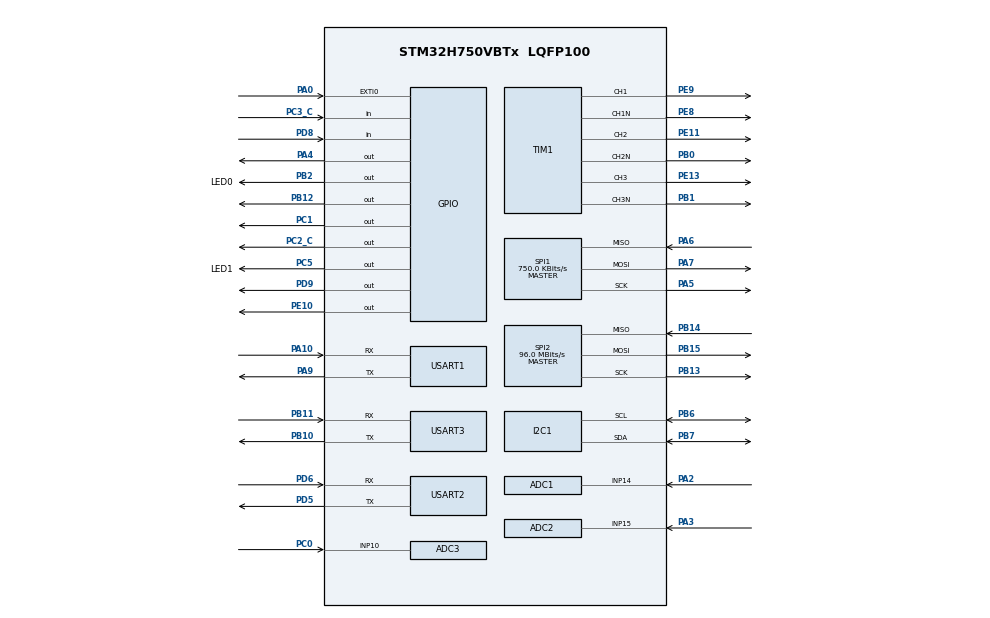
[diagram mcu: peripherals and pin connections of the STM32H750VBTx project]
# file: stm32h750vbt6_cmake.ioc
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ADC1.Channel-5\#ChannelRegularConversion=ADC_CHANNEL_14
ADC1.ClockPrescaler=ADC_CLOCK_ASYNC_DIV1
ADC1.DiscontinuousConvMode=ENABLE
ADC1.NbrOfConversion=1
ADC1.NbrOfConversionFlag=1
ADC1.NbrOfDiscConversion=1
ADC1.OffsetNumber-5\#ChannelRegularConversion=ADC_OFFSET_NONE
ADC1.OffsetSignedSaturation-5\#ChannelRegularConversion=DISABLE
ADC1.OversamplingMode=DISABLE
ADC1.Rank-5\#ChannelRegularConversion=1
ADC1.Ratio=1
ADC1.Resolution=ADC_RESOLUTION_16B
ADC1.SamplingTime-5\#ChannelRegularConversion=ADC_SAMPLETIME_1CYCLE_5
ADC1.master=1
ADC2.Channel-6\#ChannelRegularConversion=ADC_CHANNEL_15
ADC2.NbrOfConversionFlag=1
ADC2.OffsetNumber-6\#ChannelRegularConversion=ADC_OFFSET_NONE
ADC2.OffsetSignedSaturation-6\#ChannelRegularConversion=DISABLE
ADC2.Rank-6\#ChannelRegularConversion=1
ADC2.SamplingTime-6\#ChannelRegularConversion=ADC_SAMPLETIME_1CYCLE_5
ADC3.Channel-1\#ChannelRegularConversion=ADC_CHANNEL_10
ADC3.DiscontinuousConvMode=ENABLE
ADC3.NbrOfConversionFlag=1
ADC3.OffsetNumber-1\#ChannelRegularConversion=ADC_OFFSET_NONE
ADC3.OffsetSignedSaturation-1\#ChannelRegularConversion=DISABLE
ADC3.Rank-1\#ChannelRegularConversion=1
ADC3.SamplingTime-1\#ChannelRegularConversion=ADC_SAMPLETIME_1CYCLE_5
CORTEX_M7.default_mode_Activation=1
I2C1.Timing=0x307075B1
Mcu.Family=STM32H7
Mcu.Name=STM32H750VBTx
Mcu.Package=LQFP100
NVIC.ADC3_IRQn=true\:0\:0\:false\:false\:true\:true\:true\:true
NVIC.ADC_IRQn=true\:0\:0\:false\:false\:true\:true\:true\:true
NVIC.PriorityGroup=NVIC_PRIORITYGROUP_4
NVIC.SPI2_IRQn=true\:0\:0\:false\:false\:true\:true\:true\:true
NVIC.TIM1_BRK_IRQn=true\:0\:0\:false\:false\:true\:true\:true\:true
NVIC.TIM1_CC_IRQn=true\:0\:0\:false\:false\:true\:true\:true\:true
NVIC.TIM1_TRG_COM_IRQn=true\:0\:0\:false\:false\:true\:true\:true\:true
NVIC.TIM1_UP_IRQn=true\:0\:0\:false\:false\:true\:true\:true\:true
NVIC.TIM2_IRQn=true\:0\:0\:false\:false\:true\:true\:true\:true
NVIC.TIM3_IRQn=true\:0\:0\:false\:false\:true\:true\:true\:true
NVIC.TIM4_IRQn=true\:0\:0\:false\:false\:true\:true\:true\:true
NVIC.USART1_IRQn=true\:0\:0\:false\:false\:true\:true\:true\:true
NVIC.USART2_IRQn=true\:0\:0\:false\:false\:true\:true\:true\:true
NVIC.USART3_IRQn=true\:0\:0\:false\:false\:true\:true\:true\:true
PA0.Signal=GPXTI0
PA10.Mode=Asynchronous
PA10.Signal=USART1_RX
PA2.Signal=ADCx_INP14
PA3.Signal=ADCx_INP15
PA4.Signal=GPIO_Output
PA5.Mode=Full_Duplex_Master
PA5.Signal=SPI1_SCK
PA6.Mode=Full_Duplex_Master
PA6.Signal=SPI1_MISO
PA7.Mode=Full_Duplex_Master
PA7.Signal=SPI1_MOSI
PA9.Mode=Asynchronous
PA9.Signal=USART1_TX
PB0.Mode=PWM Generation2 CH2 CH2N
PB0.Signal=TIM1_CH2N
PB1.Mode=PWM Generation3 CH3 CH3N
PB1.Signal=TIM1_CH3N
PB10.Mode=Asynchronous
PB10.Signal=USART3_TX
PB11.Mode=Asynchronous
PB11.Signal=USART3_RX
PB12.Signal=GPIO_Output
PB13.Mode=Full_Duplex_Master
PB13.Signal=SPI2_SCK
PB14.Mode=Full_Duplex_Master
PB14.Signal=SPI2_MISO
PB15.Mode=Full_Duplex_Master
PB15.Signal=SPI2_MOSI
PB2.GPIO_Label=LED0
PB2.Signal=GPIO_Output
PB6.Mode=I2C
PB6.Signal=I2C1_SCL
PB7.Mode=I2C
PB7.Signal=I2C1_SDA
PC0.Signal=ADCx_INP10
PC1.Signal=GPIO_Output
PC2_C.Signal=GPIO_Output
PC3_C.Signal=GPIO_Input
PC5.GPIO_Label=LED1
PC5.Signal=GPIO_Output
PD5.Mode=Asynchronous
PD5.Signal=USART2_TX
PD6.Mode=Asynchronous
PD6.Signal=USART2_RX
PD8.Signal=GPIO_Input
PD9.Signal=GPIO_Output
PE10.Signal=GPIO_Output
PE11.Signal=S_TIM1_CH2
PE13.Signal=S_TIM1_CH3
PE8.Mode=PWM Generation1 CH1 CH1N
PE8.Signal=TIM1_CH1N
PE9.Signal=S_TIM1_CH1
PH0-OSC_IN\ (PH0).Mode=HSE-External-Oscillator
PH0-OSC_IN\ (PH0).Signal=RCC_OSC_IN
PH1-OSC_OUT\ (PH1).Mode=HSE-External-Oscillator
PH1-OSC_OUT\ (PH1).Signal=RCC_OSC_OUT
ProjectManager.HeapSize=0x200
ProjectManager.StackSize=0x400
ProjectManager.TargetToolchain=CMake
RCC.ADCFreq_Value=75000000
RCC.APB1Freq_Value=120000000
RCC.APB2Freq_Value=120000000
RCC.APB3Freq_Value=120000000
RCC.APB4Freq_Value=120000000
RCC.CortexFreq_Value=480000000
RCC.D1PPRE=RCC_APB3_DIV2
RCC.D2PPRE1=RCC_APB1_DIV2
RCC.D2PPRE2=RCC_APB2_DIV2
RCC.D3PPRE=RCC_APB4_DIV2
RCC.DIVM1=5
RCC.DIVM2=2
RCC.DIVN1=192
RCC.DIVN2=12
RCC.DIVQ1=5
RCC.HCLKFreq_Value=240000000
RCC.HPRE=RCC_HCLK_DIV2
RCC.PLL2FRACN=0
RCC.PLLFRACN=0
RCC.PLLSourceVirtual=RCC_PLLSOURCE_HSE
RCC.SYSCLKFreq_VALUE=480000000
RCC.SYSCLKSource=RCC_SYSCLKSOURCE_PLLCLK
RCC.USBFreq_Value=192000000
SH.ADCx_INP10.0=ADC3_INP10,IN10-Single-Ended
SH.ADCx_INP14.0=ADC1_INP14,IN14-Single-Ended
SH.ADCx_INP15.0=ADC2_INP15,IN15-Single-Ended
SH.S_TIM1_CH1.0=TIM1_CH1,PWM Generation1 CH1 CH1N
SH.S_TIM1_CH2.0=TIM1_CH2,PWM Generation2 CH2 CH2N
SH.S_TIM1_CH3.0=TIM1_CH3,PWM Generation3 CH3 CH3N
SPI1.BaudRatePrescaler=SPI_BAUDRATEPRESCALER_256
SPI1.CLKPhase=SPI_PHASE_2EDGE
SPI1.CalculateBaudRate=750.0 KBits/s
SPI1.DataSize=SPI_DATASIZE_8BIT
SPI1.Direction=SPI_DIRECTION_2LINES
SPI1.Mode=SPI_MODE_MASTER
SPI1.VirtualType=VM_MASTER
SPI2.CalculateBaudRate=96.0 MBits/s
SPI2.Direction=SPI_DIRECTION_2LINES
SPI2.Mode=SPI_MODE_MASTER
SPI2.VirtualType=VM_MASTER
TIM1.AutoReloadPreload=TIM_AUTORELOAD_PRELOAD_ENABLE
TIM1.Channel-PWM\ Generation1\ CH1\ CH1N=TIM_CHANNEL_1
TIM1.Channel-PWM\ Generation2\ CH2\ CH2N=TIM_CHANNEL_2
TIM1.Channel-PWM\ Generation3\ CH3\ CH3N=TIM_CHANNEL_3
TIM1.DeadTime=100
TIM3.AutoReloadPreload=TIM_AUTORELOAD_PRELOAD_ENABLE
USART1.VirtualMode-Asynchronous=VM_ASYNC
USART2.VirtualMode-Asynchronous=VM_ASYNC
USART3.VirtualMode-Asynchronous=VM_ASYNC
VP_MEMORYMAP_VS_MEMORYMAP.Mode=CurAppReg
VP_TIM1_VS_ClockSourceINT.Mode=Internal
VP_TIM2_VS_ClockSourceINT.Mode=Internal
VP_TIM3_VS_ClockSourceINT.Mode=Internal
VP_TIM4_VS_ClockSourceINT.Mode=Internal
board=custom

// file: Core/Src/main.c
/* USER CODE BEGIN Header */
/**
  ******************************************************************************
  * @file           : main.c
  * @brief          : Main program body
  ******************************************************************************
  * @attention
  *
  * Copyright (c) 2025 STMicroelectronics.
  * All rights reserved.
  *
  * This software is licensed under terms that can be found in the LICENSE file
  * in the root directory of this software component.
  * If no LICENSE file comes with this software, it is provided AS-IS.
  *
  ******************************************************************************
  */
/* USER CODE END Header */
#include "main.h"
#include "adc.h"
#include "i2c.h"
#include "spi.h"
#include "tim.h"
#include "usart.h"
#include "gpio.h"

/* USER CODE BEGIN Includes */
#include "mymain.h"

/* USER CODE END Includes */

void SystemClock_Config(void);
void PeriphCommonClock_Config(void);
static void MPU_Config(void);

int main(void)
{

  /* MPU Configuration--------------------------------------------------------*/
  MPU_Config();

  /* MCU Configuration--------------------------------------------------------*/

  /* Reset of all peripherals, Initializes the Flash interface and the Systick. */
  HAL_Init();

  /* Configure the system clock */
  SystemClock_Config();

  /* Configure the peripherals common clocks */
  PeriphCommonClock_Config();

  /* Initialize all configured peripherals */
  MX_GPIO_Init();
  MX_USART1_UART_Init();
  MX_I2C1_Init();
  MX_SPI1_Init();
  MX_TIM1_Init();
  MX_TIM2_Init();
  MX_TIM3_Init();
  MX_TIM4_Init();
  MX_USART2_UART_Init();
  MX_USART3_UART_Init();
  MX_SPI2_Init();
  MX_ADC1_Init();
  MX_ADC2_Init();
  MX_ADC3_Init();
  /* USER CODE BEGIN 2 */
   mymain();

  /* USER CODE END 2 */

  /* Infinite loop */
  while (1)
  {

    /* USER CODE BEGIN 3 */
      HAL_GPIO_TogglePin(GPIOC, GPIO_PIN_5);
      // HAL_GPIO_TogglePin(GPIOB, GPIO_PIN_2);
      HAL_Delay(1000);
  }
  /* USER CODE END 3 */
}

void SystemClock_Config(void)
{
  RCC_OscInitTypeDef RCC_OscInitStruct = {0};
  RCC_ClkInitTypeDef RCC_ClkInitStruct = {0};

  /** Supply configuration update enable
  */
  HAL_PWREx_ConfigSupply(PWR_LDO_SUPPLY);

  /** Configure the main internal regulator output voltage
  */
  __HAL_PWR_VOLTAGESCALING_CONFIG(PWR_REGULATOR_VOLTAGE_SCALE0);

  while(!__HAL_PWR_GET_FLAG(PWR_FLAG_VOSRDY)) {}

  /** Initializes the RCC Oscillators according to the specified parameters
  * in the RCC_OscInitTypeDef structure.
  */
  RCC_OscInitStruct.OscillatorType = RCC_OSCILLATORTYPE_HSE;
  RCC_OscInitStruct.HSEState = RCC_HSE_ON;
  RCC_OscInitStruct.PLL.PLLState = RCC_PLL_ON;
  RCC_OscInitStruct.PLL.PLLSource = RCC_PLLSOURCE_HSE;
  RCC_OscInitStruct.PLL.PLLM = 5;
  RCC_OscInitStruct.PLL.PLLN = 192;
  RCC_OscInitStruct.PLL.PLLP = 2;
  RCC_OscInitStruct.PLL.PLLQ = 5;
  RCC_OscInitStruct.PLL.PLLR = 2;
  RCC_OscInitStruct.PLL.PLLRGE = RCC_PLL1VCIRANGE_2;
  RCC_OscInitStruct.PLL.PLLVCOSEL = RCC_PLL1VCOWIDE;
  RCC_OscInitStruct.PLL.PLLFRACN = 0;
  if (HAL_RCC_OscConfig(&RCC_OscInitStruct) != HAL_OK)
  {
    Error_Handler();
  }

  /** Initializes the CPU, AHB and APB buses clocks
  */
  RCC_ClkInitStruct.ClockType = RCC_CLOCKTYPE_HCLK|RCC_CLOCKTYPE_SYSCLK
                              |RCC_CLOCKTYPE_PCLK1|RCC_CLOCKTYPE_PCLK2
                              |RCC_CLOCKTYPE_D3PCLK1|RCC_CLOCKTYPE_D1PCLK1;
  RCC_ClkInitStruct.SYSCLKSource = RCC_SYSCLKSOURCE_PLLCLK;
  RCC_ClkInitStruct.SYSCLKDivider = RCC_SYSCLK_DIV1;
  RCC_ClkInitStruct.AHBCLKDivider = RCC_HCLK_DIV2;
  RCC_ClkInitStruct.APB3CLKDivider = RCC_APB3_DIV2;
  RCC_ClkInitStruct.APB1CLKDivider = RCC_APB1_DIV2;
  RCC_ClkInitStruct.APB2CLKDivider = RCC_APB2_DIV2;
  RCC_ClkInitStruct.APB4CLKDivider = RCC_APB4_DIV2;

  if (HAL_RCC_ClockConfig(&RCC_ClkInitStruct, FLASH_LATENCY_4) != HAL_OK)
  {
    Error_Handler();
  }
}

void PeriphCommonClock_Config(void)
{
  RCC_PeriphCLKInitTypeDef PeriphClkInitStruct = {0};

  /** Initializes the peripherals clock
  */
  PeriphClkInitStruct.PeriphClockSelection = RCC_PERIPHCLK_ADC;
  PeriphClkInitStruct.PLL2.PLL2M = 2;
  PeriphClkInitStruct.PLL2.PLL2N = 12;
  PeriphClkInitStruct.PLL2.PLL2P = 2;
  PeriphClkInitStruct.PLL2.PLL2Q = 2;
  PeriphClkInitStruct.PLL2.PLL2R = 2;
  PeriphClkInitStruct.PLL2.PLL2RGE = RCC_PLL2VCIRANGE_3;
  PeriphClkInitStruct.PLL2.PLL2VCOSEL = RCC_PLL2VCOMEDIUM;
  PeriphClkInitStruct.PLL2.PLL2FRACN = 0;
  PeriphClkInitStruct.AdcClockSelection = RCC_ADCCLKSOURCE_PLL2;
  if (HAL_RCCEx_PeriphCLKConfig(&PeriphClkInitStruct) != HAL_OK)
  {
    Error_Handler();
  }
}

 /* MPU Configuration */

void MPU_Config(void)
{
  MPU_Region_InitTypeDef MPU_InitStruct = {0};

  /* Disables the MPU */
  HAL_MPU_Disable();

  /** Initializes and configures the Region and the memory to be protected
  */
  MPU_InitStruct.Enable = MPU_REGION_ENABLE;
  MPU_InitStruct.Number = MPU_REGION_NUMBER0;
  MPU_InitStruct.BaseAddress = 0x0;
  MPU_InitStruct.Size = MPU_REGION_SIZE_4GB;
  MPU_InitStruct.SubRegionDisable = 0x87;
  MPU_InitStruct.TypeExtField = MPU_TEX_LEVEL0;
  MPU_InitStruct.AccessPermission = MPU_REGION_NO_ACCESS;
  MPU_InitStruct.DisableExec = MPU_INSTRUCTION_ACCESS_DISABLE;
  MPU_InitStruct.IsShareable = MPU_ACCESS_SHAREABLE;
  MPU_InitStruct.IsCacheable = MPU_ACCESS_NOT_CACHEABLE;
  MPU_InitStruct.IsBufferable = MPU_ACCESS_NOT_BUFFERABLE;

  HAL_MPU_ConfigRegion(&MPU_InitStruct);
  /* Enables the MPU */
  HAL_MPU_Enable(MPU_PRIVILEGED_DEFAULT);

}

void Error_Handler(void)
{
  __disable_irq();
  while (1)
  {
  }
}
